# alb32r003x register map
Vendor: ALB; Series: ALB RT SoC
CPU: ALB XF, little endian
Registers are 32-bit, access not given, reset 0x0 unless marked. A register's access mark holds for its fields unless they carry their own. Offsets are from the block's base; [hi:lo] are bit positions; 'fields as' and 'values as' point back to an identical list.

## TIMER1 — TIMER1: General-purpose Timer 1 for timing, counting and PWM generation
Base 0x24000000
Same registers: TIMER2 0x24001000, TIMER3 0x24002000, TIMER4 0x24003000
0x00 TimerCh1LoadCount — Value to be loaded into TimerCh1
0x04 TimerCh1CurrentValue — Current value of TimerCh1
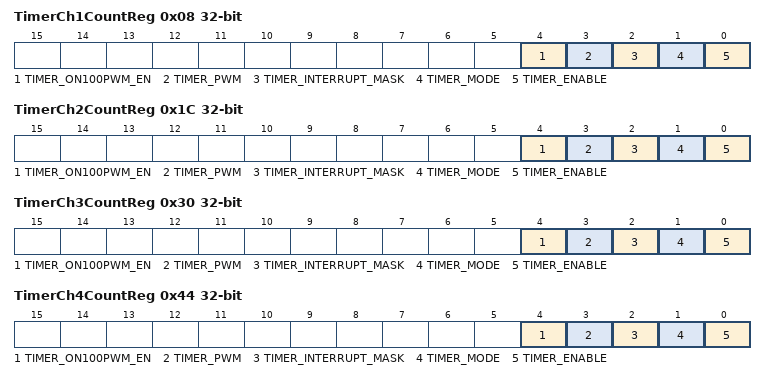
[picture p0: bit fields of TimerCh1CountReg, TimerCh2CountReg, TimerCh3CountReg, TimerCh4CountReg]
0x08 TimerCh1CountReg rw — Control Register for TimerCh1. This register controls enabling, operating mode (free-running or defined-count),…
  [4] TIMER_ON100PWM_EN — Optional. Allows user to enable or disable the usage of Timer 0% and 100% mode feature.
    1=ENABLED (Timer 0% and 100% PWM duty cycle mode is enabled); 0=DISABLE (Timer 0% and 100% PWM duty cycle mode is disabled); 1=ENABLED (Timer 0% and 100% PWM duty cycle mode is enabled); 0=DISABLE (Timer 0% and 100% PWM duty cycle mode is disabled); 1=ENABLED (Timer 0% and 100% PWM duty cycle mode is enabled); 0=DISABLE (Timer 0% and 100% PWM duty cycle mode is disabled); 1=ENABLED (Timer 0% and 100% PWM duty cycle mode is enabled); 0=DISABLE (Timer 0% and 100% PWM duty cycle mode is disabled)
  [3] TIMER_PWM — Pulse Width Modulation of timer_1_toggle output.
    1=ENABLED (PWM for timer_1_toggle o/p is enabled); 0=DISABLE (PWM for timer_1_toggle o/p is disabled); 1=ENABLED (PWM for timer_2_toggle o/p is enabled); 0=DISABLE (PWM for timer_2_toggle o/p is disabled); 1=ENABLED (PWM for timer_3_toggle o/p is enabled); 0=DISABLE (PWM for timer_3_toggle o/p is disabled); 1=ENABLED (PWM for timer_4_toggle o/p is enabled); 0=DISABLE (PWM for timer_4_toggle o/p is disabled)
  [2] TIMER_INTERRUPT_MASK — Timer interrupt mask for TimerCh1
    1=MASKED (TimerCh1 interrupt is masked); 0=UNMASKED (TimerCh1 interrupt is unmasked); 1=MASKED (TimerCh2 interrupt is masked); 0=UNMASKED (TimerCh2 interrupt is unmasked); 1=MASKED (TimerCh3 interrupt is masked); 0=UNMASKED (TimerCh3 interrupt is unmasked); 1=MASKED (TimerCh4 interrupt is masked); 0=UNMASKED (TimerCh4 interrupt is unmasked)
  [1] TIMER_MODE — Timer mode for TimerCh1
    1=USER_DEFINED (User-Defined mode of operation); 0=FREE_RUNNING (Free Running mode of operationValue After Reset:); 1=USER_DEFINED (User-Defined mode of operation); 0=FREE_RUNNING (Free Running mode of operationValue After Reset:); 1=USER_DEFINED (User-Defined mode of operation); 0=FREE_RUNNING (Free Running mode of operationValue After Reset:); 1=USER_DEFINED (User-Defined mode of operation); 0=FREE_RUNNING (Free Running mode of operationValue After Reset:)
  [0] TIMER_ENABLE — Timer enable for TimerCh1
    1=ENABLED (TimerCh1 is enabled); 0=DISABLE (TimerCh1 is disabled); 1=ENABLED (TimerCh2 is enabled); 0=DISABLE (TimerCh2 is disabled); 1=ENABLED (TimerCh3 is enabled); 0=DISABLE (TimerCh3 is disabled); 1=ENABLED (TimerCh4 is enabled); 0=DISABLE (TimerCh4 is disabled)
0x0C TimerCh1EOI — Clears the interrupt from TimerCh1
0x10 TimerCh1IntStatus ro — TimerCh1IntStatus: Consolidated interrupt status register indicating all active TimerCh1 events
  [0] TimerCh1IntStatus — Contains the interrupt status for TimerCh1.
    1=ACTIVE (TimerCh1 Interrupt is active.); 0=INACTIVE (TimerCh1 Interrupt is inactive.)
0x14 TimerCh2LoadCount — Value to be loaded into TimerCh2
0x18 TimerCh2CurrentValue — Current value of TimerCh2
0x1C TimerCh2CountReg rw — Control Register for TimerCh2. This register controls enabling, operating mode (free-running or defined-count),…
  fields as TimerCh1CountReg
0x20 TimerCh2EOI — Clears the interrupt from TimerCh2
0x24 TimerCh2IntStatus ro — TimerCh2IntStatus: Consolidated interrupt status register indicating all active TimerCh2 events
  [0] TimerCh2IntStatus — Contains the interrupt status for TimerCh2.
    1=ACTIVE (TimerCh2 Interrupt is active.); 0=INACTIVE (TimerCh2 Interrupt is inactive.)
0x28 TimerCh3LoadCount — Value to be loaded into TimerCh3
0x2C TimerCh3CurrentValue — Current value of TimerCh3
0x30 TimerCh3CountReg rw — Control Register for TimerCh3. This register controls enabling, operating mode (free-running or defined-count),…
  fields as TimerCh1CountReg
0x34 TimerCh3EOI — Clears the interrupt from TimerCh3
0x38 TimerCh3IntStatus ro — TimerCh3IntStatus: Consolidated interrupt status register indicating all active TimerCh3 events
  [0] TimerCh3IntStatus — Contains the interrupt status for TimerCh3.
    1=ACTIVE (TimerCh3 Interrupt is active.); 0=INACTIVE (TimerCh3 Interrupt is inactive.)
0x3C TimerCh4LoadCount — Value to be loaded into TimerCh4
0x40 TimerCh4CurrentValue — Current value of TimerCh4
0x44 TimerCh4CountReg rw — Control Register for TimerCh4. This register controls enabling, operating mode (free-running or defined-count),…
  fields as TimerCh1CountReg
0x48 TimerCh4EOI — Clears the interrupt from TimerCh4
0x4C TimerCh4IntStatus ro — TimerCh4IntStatus: Consolidated interrupt status register indicating all active TimerCh4 events
  [0] TimerCh4IntStatus — Contains the interrupt status for TimerCh4.
    1=ACTIVE (TimerCh4 Interrupt is active.); 0=INACTIVE (TimerCh4 Interrupt is inactive.)
0xA0 TIMS_INSTAT ro — TIMS_INSTAT: Masked interrupt status register showing pending timer events after masking
  [8:0] TimerIntStatus — Contains the Interrupt status of all timers in the component.
    1=ACTIVE (Timer_intr(_n) is active); 0=INACTIVE (Timer_intr(_n) is inactive)
0xA4 TIMS_EOI — TIMS_EOI: End-of-interrupt register for software acknowledge and event clearing
0xA8 TIMS_RAWINSTAT ro — TIMS_RAWINSTAT: Raw interrupt status register reflecting unmasked timer events
  [8:0] TIMERSRAWINTSTAT — The register contains the unmasked interrupt status of all timers in the component.
    1=ACTIVE (Raw Timer_intr(_n) is active); 0=INACTIVE (Raw Timer_intr(_n) is inactive)
0xAC COMP_VERSION — COMP_VERSION: Component-version register delivering IP release and feature-revision identifiers
